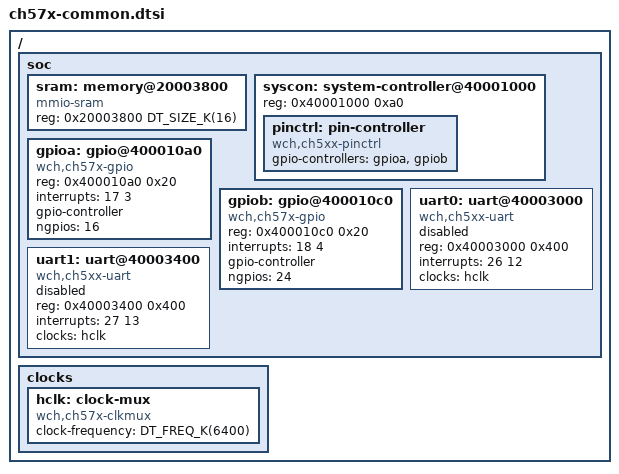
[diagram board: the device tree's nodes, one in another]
/*
 * Copyright (c) 2023-2024 Chen Xingyu <hi@xingrz.me>
 * SPDX-License-Identifier: Apache-2.0
 */

#include <mem.h>
#include <freq.h>

#include <wch/qingke-v3.dtsi>

/ {
	soc {
		sram: memory@20003800 {
			compatible = "mmio-sram";
			reg = <0x20003800 DT_SIZE_K(16)>;
		};

		syscon: system-controller@40001000 {
			reg = <0x40001000 0xa0>;

			pinctrl: pin-controller {
				compatible = "wch,ch5xx-pinctrl";
				gpio-controllers = <&gpioa>, <&gpiob>;
			};
		};

		gpioa: gpio@400010a0 {
			compatible = "wch,ch57x-gpio";
			reg = <0x400010a0 0x20>;
			interrupts = <17 3>;
			gpio-controller;
			#gpio-cells = <2>;
			ngpios = <16>;
		};

		gpiob: gpio@400010c0 {
			compatible = "wch,ch57x-gpio";
			reg = <0x400010c0 0x20>;
			interrupts = <18 4>;
			gpio-controller;
			#gpio-cells = <2>;
			ngpios = <24>;
		};

		uart0: uart@40003000 {
			compatible = "wch,ch5xx-uart";
			reg = <0x40003000 0x400>;
			interrupts = <26 12>;
			clocks = <&hclk>;
			status = "disabled";
		};

		uart1: uart@40003400 {
			compatible = "wch,ch5xx-uart";
			reg = <0x40003400 0x400>;
			interrupts = <27 13>;
			clocks = <&hclk>;
			status = "disabled";
		};
	};

	clocks {
		hclk: clock-mux {
			compatible = "wch,ch57x-clkmux";
			clock-frequency = <DT_FREQ_K(6400)>;
			#clock-cells = <0>;
		};
	};
};
